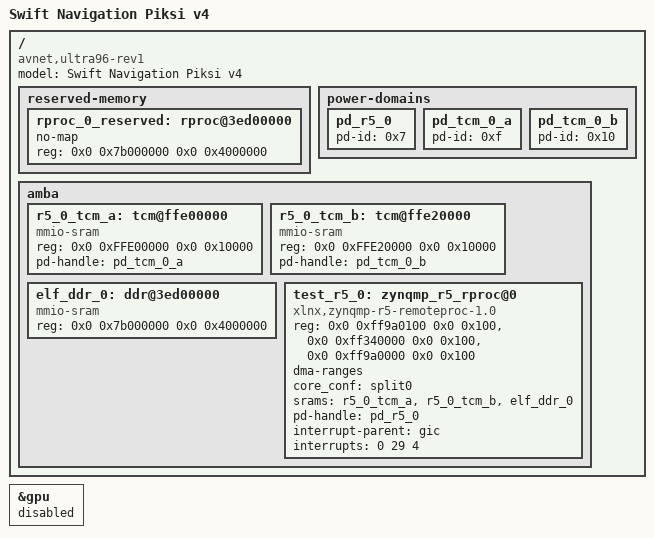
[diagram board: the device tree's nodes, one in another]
// SPDX-License-Identifier: GPL-2.0+
/*
 * dts file for Avnet Ultra96 rev1
 *
 * (C) Copyright 2018, Xilinx, Inc.
 *
 * Michal Simek <michal.simek@xilinx.com>
 */

/dts-v1/;

#include "xilinx/zynqmp-zcu100-revC.dts"

/ {
	model = "Swift Navigation Piksi v4";
	compatible = "avnet,ultra96-rev1", "avnet,ultra96",
		     "xlnx,zynqmp-zcu100-revC", "xlnx,zynqmp-zcu100",
		     "xlnx,zynqmp";

	reserved-memory {
		#address-cells = <2>;
		#size-cells = <2>;
		ranges;
		rproc_0_reserved: rproc@3ed00000 {
			no-map;
			reg = <0x0 0x7b000000 0x0 0x4000000>;
		};
	};

	power-domains {
		pd_r5_0: pd_r5_0 {
		#power-domain-cells = <0x0>;
		pd-id = <0x7>;
		};
		pd_tcm_0_a: pd_tcm_0_a {
		#power-domain-cells = <0x0>;
		pd-id = <0xf>;
		};
		pd_tcm_0_b: pd_tcm_0_b {
		#power-domain-cells = <0x0>;
		pd-id = <0x10>;
		};
	};

	amba {
		r5_0_tcm_a: tcm@ffe00000 {
			compatible = "mmio-sram";
			reg = <0x0 0xFFE00000 0x0 0x10000>;
			pd-handle = <&pd_tcm_0_a>;
		};
		r5_0_tcm_b: tcm@ffe20000 {
			compatible = "mmio-sram";
			reg = <0x0 0xFFE20000 0x0 0x10000>;
			pd-handle = <&pd_tcm_0_b>;
		};
		elf_ddr_0: ddr@3ed00000 {
			compatible = "mmio-sram";
			reg = <0x0 0x7b000000 0x0 0x4000000>;
		};
		test_r5_0: zynqmp_r5_rproc@0 {
			compatible = "xlnx,zynqmp-r5-remoteproc-1.0";
			reg = <0x0 0xff9a0100 0x0 0x100>,
			      <0x0 0xff340000 0x0 0x100>,
			      <0x0 0xff9a0000 0x0 0x100>;
			reg-names = "rpu_base", "ipi", "rpu_glbl_base";
			dma-ranges;
			core_conf = "split0";
			srams = <&r5_0_tcm_a &r5_0_tcm_b &elf_ddr_0>;
			pd-handle = <&pd_r5_0>;
			interrupt-parent = <&gic>;
			interrupts = <0 29 4>;
		};
	};
};

&gpu {
	status = "disabled";
};

